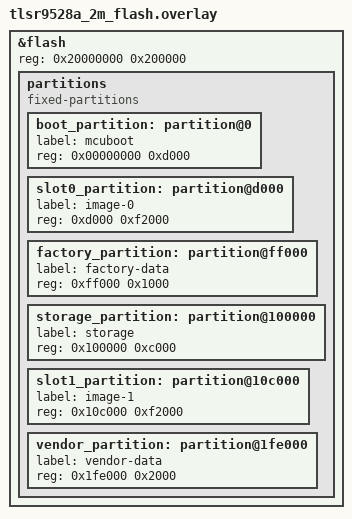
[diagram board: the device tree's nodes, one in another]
&flash {
	reg = <0x20000000 0x200000>;

	/delete-node/ partitions;
	partitions {
		compatible = "fixed-partitions";
		#address-cells = <1>;
		#size-cells = <1>;

		boot_partition: partition@0 {
			label = "mcuboot";
			reg = <0x00000000 0xd000>;
		};
		slot0_partition: partition@d000 {
			label = "image-0";
			reg = <0xd000 0xf2000>;
		};
		factory_partition: partition@ff000 {
			label = "factory-data";
			reg = <0xff000 0x1000>;
		};
		storage_partition: partition@100000 {
			label = "storage";
			reg = <0x100000 0xc000>;
		};
		slot1_partition: partition@10c000 {
			label = "image-1";
			reg = <0x10c000 0xf2000>;
		};
		vendor_partition: partition@1fe000 {
			label = "vendor-data";
			reg = <0x1fe000 0x2000>;
		};
	};
};
